AUTOSAR XML (schema 4-0-3)
package /ComponentTypes
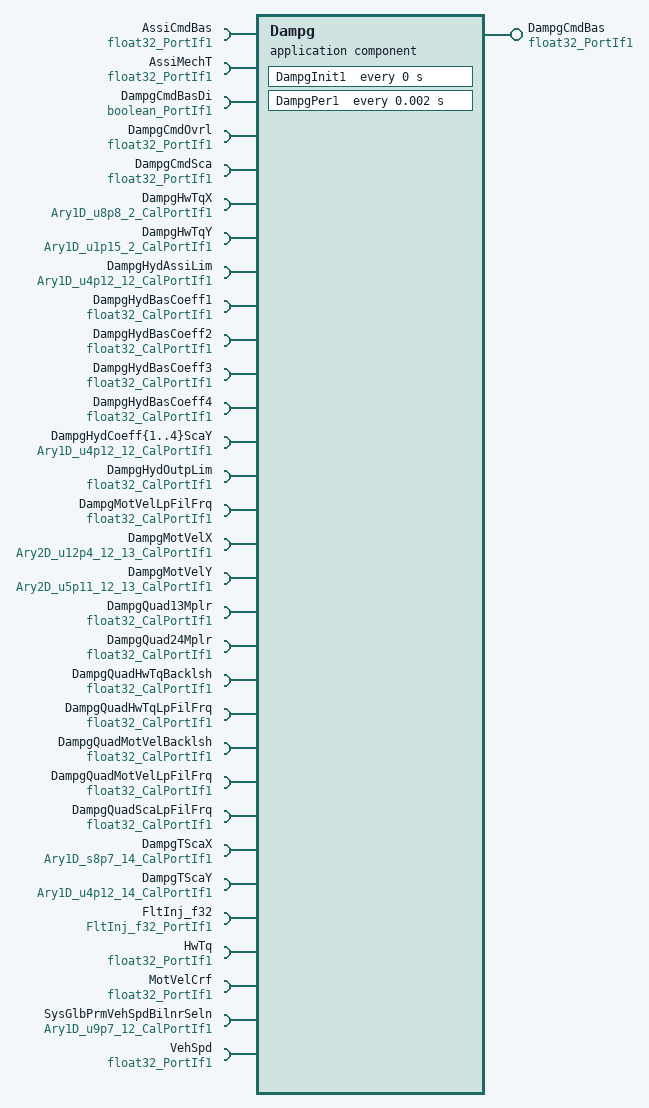
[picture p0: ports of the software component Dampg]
  application sw component type Dampg
    provide port DampgCmdBas: nonqueued-sender-com-spec{data-element=Val, init-value=0}, provided-interface=float32_PortIf1
    34 x require port:
      AssiCmdBas: nonqueued-receiver-com-spec{data-element=Val, filter=data-filter-type=ALWAYS, init-value=0}, required-interface=float32_PortIf1
      AssiMechT: nonqueued-receiver-com-spec{data-element=Val, filter=data-filter-type=ALWAYS, init-value=0}, required-interface=float32_PortIf1
      DampgCmdBasDi: nonqueued-receiver-com-spec{data-element=Logl, filter=data-filter-type=ALWAYS, init-value=0}, required-interface=boolean_PortIf1
      DampgCmdOvrl: nonqueued-receiver-com-spec{data-element=Val, filter=data-filter-type=ALWAYS, init-value=0}, required-interface=float32_PortIf1
      DampgCmdSca: nonqueued-receiver-com-spec{data-element=Val, filter=data-filter-type=ALWAYS, init-value=1}, required-interface=float32_PortIf1
      DampgHwTqX: parameter-require-com-spec{init-value=[2048, 2560], parameter=Ary1D}, required-interface=Ary1D_u8p8_2_CalPortIf1
      DampgHwTqY: parameter-require-com-spec{init-value=[32768, 0], parameter=Ary1D}, required-interface=Ary1D_u1p15_2_CalPortIf1
      DampgHydAssiLim: parameter-require-com-spec{init-value=12 x 36045, parameter=Ary1D}, required-interface=Ary1D_u4p12_12_CalPortIf1
      DampgHydBasCoeff1: parameter-require-com-spec{init-value=0.0005, parameter=Val}, required-interface=float32_CalPortIf1
      DampgHydBasCoeff2: parameter-require-com-spec{init-value=2e-05, parameter=Val}, required-interface=float32_CalPortIf1
      DampgHydBasCoeff3: parameter-require-com-spec{init-value=0.006, parameter=Val}, required-interface=float32_CalPortIf1
      DampgHydBasCoeff4: parameter-require-com-spec{init-value=9e-06, parameter=Val}, required-interface=float32_CalPortIf1
      DampgHydCoeff{1..4}ScaY: parameter-require-com-spec{init-value=12 x 4096, parameter=Ary1D}, required-interface=Ary1D_u4p12_12_CalPortIf1
      DampgHydOutpLim: parameter-require-com-spec{init-value=0, parameter=Val}, required-interface=float32_CalPortIf1
      DampgMotVelLpFilFrq: parameter-require-com-spec{init-value=15, parameter=Val}, required-interface=float32_CalPortIf1
      DampgMotVelX: parameter-require-com-spec{init-value=12 x [33, 163, 342, 554, 872, 1260, 1663, 2032, 2401, 2771, 3509, 4433, 5910], parameter=Ary2D}, required-interface=Ary2D_u12p4_12_13_CalPortIf1
      DampgMotVelY: parameter-require-com-spec{init-value=[13 x 0, 13 x 0, 13 x 0, 13 x 0, [0, 0, 1, 3, 7, 14, 24, 36, 50, 67, 107, 171, 304], [1, 5, 13, 25, 48, 85, 132, 184, 245, 313, 476, 725, 1233], [5, 25, 54, 93, 159, 251, 360, 472, 597, 733, 1041, 1493, 2370], [10, 49, 106, 180, 301, 467, 659, 855, 1068, 1299, 1814, 2559, 3981], [10, 49, 106, 180, 301, 467, 659, 855, 1068, 1299, 1814, 2559, 3981], [10, 49, 106, 180, 301, 467, 659, 855, 1068, 1299, 1814, 2559, 3981], [10, 49, 106, 180, 301, 467, 659, 855, 1068, 1299, 1814, 2559, 3981], [10, 49, 106, 180, 301, 467, 659, 855, 1068, 1299, 1814, 2559, 3981]], parameter=Ary2D}, required-interface=Ary2D_u5p11_12_13_CalPortIf1
      DampgQuad13Mplr: parameter-require-com-spec{init-value=1, parameter=Val}, required-interface=float32_CalPortIf1
      DampgQuad24Mplr: parameter-require-com-spec{init-value=1, parameter=Val}, required-interface=float32_CalPortIf1
      DampgQuadHwTqBacklsh: parameter-require-com-spec{init-value=0, parameter=Val}, required-interface=float32_CalPortIf1
      DampgQuadHwTqLpFilFrq: parameter-require-com-spec{init-value=15, parameter=Val}, required-interface=float32_CalPortIf1
      DampgQuadMotVelBacklsh: parameter-require-com-spec{init-value=0, parameter=Val}, required-interface=float32_CalPortIf1
      DampgQuadMotVelLpFilFrq: parameter-require-com-spec{init-value=15, parameter=Val}, required-interface=float32_CalPortIf1
      DampgQuadScaLpFilFrq: parameter-require-com-spec{init-value=15, parameter=Val}, required-interface=float32_CalPortIf1
      DampgTScaX: parameter-require-com-spec{init-value=[-5120, -4480, -3840, -2560, -1280, 0, 1280, 2560, 3840, 5120, 6400, 7680, 8960, 11520], parameter=Ary1D}, required-interface=Ary1D_s8p7_14_CalPortIf1
      DampgTScaY: parameter-require-com-spec{init-value=14 x 4096, parameter=Ary1D}, required-interface=Ary1D_u4p12_14_CalPortIf1
      FltInj_f32: client-com-spec=Oper, required-interface=FltInj_f32_PortIf1
      HwTq: nonqueued-receiver-com-spec{data-element=Val, filter=data-filter-type=ALWAYS, init-value=0}, required-interface=float32_PortIf1
      MotVelCrf: nonqueued-receiver-com-spec{data-element=Val, filter=data-filter-type=ALWAYS, init-value=0}, required-interface=float32_PortIf1
      SysGlbPrmVehSpdBilnrSeln: parameter-require-com-spec{init-value=[0, 640, 1920, 3840, 7680, 10240, 12800, 15360, 19200, 23040, 25600, 28160], parameter=Ary1D}, required-interface=Ary1D_u9p7_12_CalPortIf1
      VehSpd: nonqueued-receiver-com-spec{data-element=Val, filter=data-filter-type=ALWAYS, init-value=0}, required-interface=float32_PortIf1
    behavior Dampg_InternalBehavior: port-api-option{enable-take-address=false, indirect-api=false, port=DampgCmdSca}
      ar-typed-per-instance-memorys:
        15 x data, all with sw-calibration-access=READ-ONLY:
          dDampgAssiMechTSca: type=float32
          dDampgCoeff{1..4}Term: type=float32
          dDampgHwTqSca: type=float32
          dDampgMotVelDampgCmd: type=float32
          dDampgQuadHwTqBacklsh: type=float32
          dDampgQuadMotVelBacklsh: type=float32
          MotVelDampgLpFil: type=FilLpRec1
          PrevHwTqBacklshOutp: type=float32
          PrevMotVelBacklshOutp: type=float32
          QuadDampgHwTqLpFil: type=FilLpRec1
          QuadDampgMotVelLpFil: type=FilLpRec1
          QuadDampgScaLpFil: type=FilLpRec1
      timing event Dampg_InitEvent: start-on-event=DampgInit1, period=0
      timing event TMT_DampgPer1: start-on-event=DampgPer1, period=0.002
      runnable DampgInit1
      runnable DampgPer1
        data-receive-point-by-arguments:
          8 x access:
            REC_AssiCmdBas_Val_1: accessed-variable=AssiCmdBas.Val
            REC_AssiMechT_Val_1: accessed-variable=AssiMechT.Val
            REC_DampgCmdBasDi_Logl_1: accessed-variable=DampgCmdBasDi.Logl
            REC_DampgCmdOvrl_Val_1: accessed-variable=DampgCmdOvrl.Val
            REC_DampgCmdSca_Val_1: accessed-variable=DampgCmdSca.Val
            REC_HwTq_Val_1: accessed-variable=HwTq.Val
            REC_MotVelCrf_Val_1: accessed-variable=MotVelCrf.Val
            REC_VehSpd_Val_1: accessed-variable=VehSpd.Val
        data-send-points:
          access SEND_DampgCmdBas_Val_1: accessed-variable=DampgCmdBas.Val
        sync call SC_FltInj_f32_Oper_1: operation=FltInj_f32.Oper, timeout=0
  swc implementation Dampg_Implementation: behavior=Dampg_InternalBehavior
    code-descriptors:
      code Default: artifact-descriptors=autosar-engineering-object={short-label=Default, category=SWSRC}
